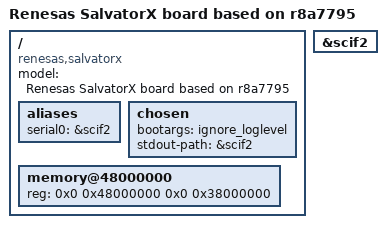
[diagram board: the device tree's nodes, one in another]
/*
 * Device Tree Source for the SalvatorX board
 *
 * Copyright (C) 2015 Renesas Electronics Corp.
 *
 * This file is licensed under the terms of the GNU General Public License
 * version 2.  This program is licensed "as is" without any warranty of any
 * kind, whether express or implied.
 */

/dts-v1/;
#include "r8a7795.dtsi"

/ {
	model = "Renesas SalvatorX board based on r8a7795";
	compatible = "renesas,salvatorx", "renesas,r8a7795";

	aliases {
		serial0 = &scif2;
	};

	chosen {
		bootargs = "ignore_loglevel";
		stdout-path = &scif2;
	};

	memory@48000000 {
		device_type = "memory";
		/* first 128MB is reserved for secure area. */
		reg = <0x0 0x48000000 0x0 0x38000000>;
	};
};

&scif2 {
	status = "okay";
};
